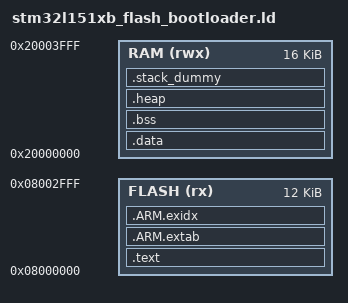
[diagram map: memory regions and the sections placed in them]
/* Memory regions.*/ 
MEMORY
{
  FLASH (rx) : ORIGIN = 0x08000000, LENGTH = 12K
  RAM (rwx)  : ORIGIN = 0x20000000, LENGTH = 16K
}

/* Entry Point */
ENTRY(Reset_Handler)

_estack = 0x20000000 + 16K;

/* Define output sections */
SECTIONS
{
	.text :
	{
		KEEP(*(.isr_vector))
		*(.text*)

		KEEP(*(.init))
		KEEP(*(.fini))

		/* .ctors */
		*crtbegin.o(.ctors)
		*crtbegin?.o(.ctors)
		*(EXCLUDE_FILE(*crtend?.o *crtend.o) .ctors)
		*(SORT(.ctors.*))
		*(.ctors)

		/* .dtors */
 		*crtbegin.o(.dtors)
 		*crtbegin?.o(.dtors)
 		*(EXCLUDE_FILE(*crtend?.o *crtend.o) .dtors)
 		*(SORT(.dtors.*))
 		*(.dtors)

		*(.rodata*)

		KEEP(*(.eh_frame*))
	} > FLASH

	.ARM.extab : 
	{
		*(.ARM.extab* .gnu.linkonce.armextab.*)
	} > FLASH

	__exidx_start = .;
	.ARM.exidx :
	{
		*(.ARM.exidx* .gnu.linkonce.armexidx.*)
	} > FLASH
	__exidx_end = .;
	__etext = .;
	
	/* used by the startup to initialize data */
	_sidata = __etext;
		
	.data : AT (__etext)
	{
		__data_start__ = .;
		_sdata = .;
		*(vtable)
		*(.data*)

		. = ALIGN(4);
		/* preinit data */
		PROVIDE_HIDDEN (__preinit_array_start = .);
		KEEP(*(.preinit_array))
		PROVIDE_HIDDEN (__preinit_array_end = .);

		. = ALIGN(4);
		/* init data */
		PROVIDE_HIDDEN (__init_array_start = .);
		KEEP(*(SORT(.init_array.*)))
		KEEP(*(.init_array))
		PROVIDE_HIDDEN (__init_array_end = .);


		. = ALIGN(4);
		/* finit data */
		PROVIDE_HIDDEN (__fini_array_start = .);
		KEEP(*(SORT(.fini_array.*)))
		KEEP(*(.fini_array))
		PROVIDE_HIDDEN (__fini_array_end = .);

		KEEP(*(.jcr*))
		. = ALIGN(4);
		/* All data end */
		__data_end__ = .;
		_edata = .;
	} > RAM

	.bss :
	{
		. = ALIGN(4);
		__bss_start__ = .;
		_sbss = .;
		*(.bss*)
		*(COMMON)
		. = ALIGN(4);
		__bss_end__ = .;
		_ebss = .;
	} > RAM
	
	.heap (COPY):
	{
		__end__ = .;
		PROVIDE(_end = .);
		PROVIDE(end = .);
		*(.heap*)
		__HeapLimit = .;
	} > RAM

	/* .stack_dummy section doesn't contains any symbols. It is only
	 * used for linker to calculate size of stack sections, and assign
	 * values to stack symbols later */
	.stack_dummy (COPY):
	{
		*(.stack*)
	} > RAM

	/* Set stack top to end of RAM, and stack limit move down by
	 * size of stack_dummy section */
	__StackTop = ORIGIN(RAM) + LENGTH(RAM);
	__StackLimit = __StackTop - SIZEOF(.stack_dummy);
	PROVIDE(__stack = __StackTop);
	
	/* Check if data + heap + stack exceeds RAM limit */
	ASSERT(__StackLimit >= __HeapLimit, "region RAM overflowed with stack")
}
